# CONTROLSS_CMPSSA8_CONTROLSS_CMPSSA8 register map
Vendor: Texas Instruments
Peripheral module from a debugger description file (folder AM263).
Registers are 16-bit, read-write, reset 0x0 unless marked. A register's access mark holds for its fields unless they carry their own. Offsets are as the file gives them; lines under a group give offsets from that group; [hi:lo] are bit positions; {n}, {i} and the like mark numbered series; 'fields as' and 'values as' point back to an identical list; <NAME> marks a mode.

## CONTROLSS_CMPSSA8_CONTROLSS_CMPSSA8
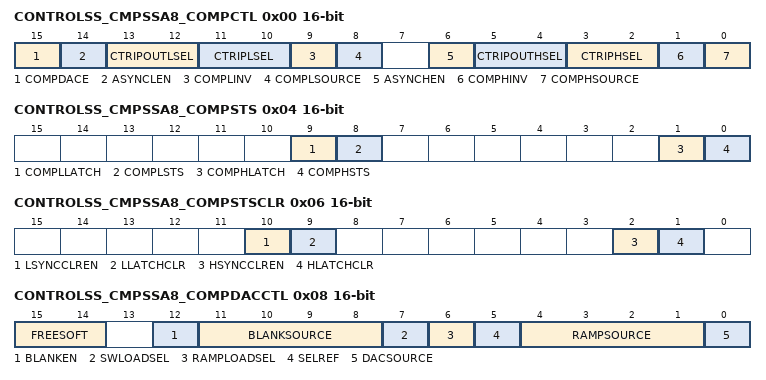
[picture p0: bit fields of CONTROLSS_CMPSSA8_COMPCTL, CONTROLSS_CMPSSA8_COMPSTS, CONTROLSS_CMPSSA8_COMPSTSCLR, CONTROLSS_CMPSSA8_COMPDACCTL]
0x00 CONTROLSS_CMPSSA8_COMPCTL
  [15] COMPDACE — Comparator/DAC enable. 0 Comparator/DAC disabled 1 Comparator/DAC enabled
  [14] ASYNCLEN — Low comparator asynchronous path enable. Allows asynchronous comparator output to feed into OR gate with latched digital filter signal when CTRIPLSEL=3 or CTRIPOUTLSEL=3. 0 Asynchronous comparator output does not feed into OR gate with latched digital filter output 1 Asynchronous comparator output feeds into OR gate with latched digital filter output
  [13:12] CTRIPOUTLSEL — Low comparator CTRIPOUTL source select. 0 Asynchronous comparator output drives CTRIPOUTL 1 Synchronous comparator output drives CTRIPOUTL 2 Output of digital filter drives CTRIPOUTL 3 Latched output of digital filter drives CTRIPOUTL
  [11:10] CTRIPLSEL — Low comparator CTRIPL source select. 0 Asynchronous comparator output drives CTRIPL 1 Synchronous comparator output drives CTRIPL 2 Output of digital filter drives CTRIPL 3 Latched output of digital filter drives CTRIPL
  [9] COMPLINV — Low comparator output invert. 0 Output of comparator is not inverted 1 Output of comparator is inverted
  [8] COMPLSOURCE — CompL Pos Mux Select0 positive mux selects INL_3p3v voltage (default)1 postive mux selects INH_3p3v
  [6] ASYNCHEN — High comparator asynchronous path enable. Allows asynchronous comparator output to feed into OR gate with latched digital filter signal when CTRIPHSEL=3 or CTRIPOUTHSEL=3. 0 Asynchronous comparator output does not feed into OR gate with latched digital filter output 1 Asynchronous comparator output feeds into OR gate with latched digital filter output
  [5:4] CTRIPOUTHSEL — High comparator CTRIPOUTH source select. 0 Asynchronous comparator output drives CTRIPOUTH 1 Synchronous comparator output drives CTRIPOUTH 2 Output of digital filter drives CTRIPOUTH 3 Latched output of digital filter drives CTRIPOUTH
  [3:2] CTRIPHSEL — High comparator CTRIPH source select. 0 Asynchronous comparator output drives CTRIPH 1 Synchronous comparator output drives CTRIPH 2 Output of digital filter drives CTRIPH 3 Latched output of digital filter drives CTRIPH
  [1] COMPHINV — High comparator output invert. 0 Output of comparator is not inverted 1 Output of comparator is inverted
  [0] COMPHSOURCE — CompH neg Mux slect0 negative mux selects DAC voltage (default)1 negative mux selects INL_3p3v
0x02 CONTROLSS_CMPSSA8_COMPHYSCTL
  [3:0] COMPHYS — Comparator hysteresis. Sets the amount of hysteresis on the comparator inputs. 0 None 1 Set to typical hysteresis 2 Set to 2x of typical hysteresis 3 Set to 3x of typical hysteresis 4 Set to 4x of typical hysteresis others : undefined
0x04 CONTROLSS_CMPSSA8_COMPSTS ro
  [9] COMPLLATCH — Latched value of low comparator digital filter output
  [8] COMPLSTS — Low comparator digital filter output
  [1] COMPHLATCH — Latched value of high comparator digital filter output
  [0] COMPHSTS — High comparator digital filter output
0x06 CONTROLSS_CMPSSA8_COMPSTSCLR access not given
  [10] LSYNCCLREN rw — Low comparator latch EPWMSYNCPER clear. Enable EPWMSYNCPER reset of low comparator digital filter output latch COMPSTS[COMPLLATCH]. 0 EPWMSYNCPER will not reset latch 1 EPWMSYNCPER will reset latch
  [9] LLATCHCLR — Low comparator latch software clear. Perform software reset of low comparator digital filter output latch COMPSTS[COMPLLATCH]. Reads always return 0. 0 No effect 1 Generate a single pulse of latch reset signal for COMPSTS[COMPLLATCH] (access RW RRETURNS0S)
  [2] HSYNCCLREN rw — High comparator latch EPWMSYNCPER clear. Enable EPWMSYNCPER reset of high comparator digital filter output latch COMPSTS[COMPHLATCH]. 0 EPWMSYNCPER will not reset latch 1 EPWMSYNCPER will reset latch
  [1] HLATCHCLR — High comparator latch software clear. Perform software reset of high comparator digital filter output latch COMPSTS[COMPHLATCH]. Reads always return 0. 0 No effect 1 Generate a single pulse of latch reset signal for COMPSTS[COMPHLATCH] (access RW RRETURNS0S)
0x08 CONTROLSS_CMPSSA8_COMPDACCTL
  [15:14] FREESOFT — Free-run or software-run emulation behavior. Behavior of the ramp generator during emulation suspend. 00b Ramp generator stops immediately during emulation suspend 01b Ramp generator completes current ramp and stops at next EPWMSYNCPER during emulation suspend 1Xb Ramp generator runs freely
  [12] BLANKEN — EPWMBLANK enable. This bit enables the EPWMBLANK signal. 0 EPWMBLANK signal is disabled. 1 EPWMBLANK signal is enabled.
  [11:8] BLANKSOURCE — EPWMBLANK source select. This bit field determines which EPWMnBLANK is passed on as the EPWMBLANK signal. Where n represents the maximum number of EPWMBLANK signals available on the device: 0 EPWM1BLANK 1 EPWM2BLANK 2 EPWM3BLANK ... n-1 EPWMnBLANK
  [7] SWLOADSEL — Software load select. Determines whether DACxVALA is updated from DACxVALS on SYSCLK or EPWMSYNCPER. 0 DACxVALA is updated from DACxVALS on SYSCLK 1 DACxVALA is updated from DACxVALS on EPWMSYNCPER
  [6] RAMPLOADSEL — Ramp load select. Determines whether RAMPSTS is updated from RAMPMAXREFA or RAMPMAXREFS when COMPSTS[COMPHSTS] is triggered. 0 RAMPSTS is loaded from RAMPMAXREFA 1 RAMPSTS is loaded from RAMPMAXREFS
  [5] SELREF — CMPSS reference select0 vref_1p8v as reference voltage (default)1 vdd_1p8v as reference voltage
  [4:1] RAMPSOURCE — EPWMSYNCPER source select. Determines which EPWMnSYNCPER signal is used within the CMPSS module. Where n represents the maximum number of EPWMSYNCPER signals available on the device: 0 EPWM1SYNCPER 1 EPWM2SYNCPER 2 EPWM3SYNCPER ... n-1 EPWMnSYNCPER
  [0] DACSOURCE — DAC source select. Determines whether DACHVALA is updated from DACHVALS or from the ramp generator. 0 DACHVALA is updated from DACHVALS 1 DACHVALA is updated from the ramp generator
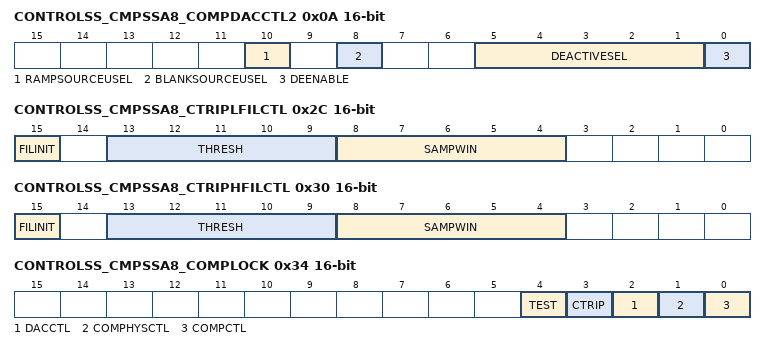
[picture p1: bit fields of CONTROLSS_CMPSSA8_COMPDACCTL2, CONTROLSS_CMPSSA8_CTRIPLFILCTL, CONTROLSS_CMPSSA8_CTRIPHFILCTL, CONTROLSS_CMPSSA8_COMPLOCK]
0x0A CONTROLSS_CMPSSA8_COMPDACCTL2
  [10] RAMPSOURCEUSEL — 0: Selects EPWM0 to 15 as RAMP source 1: Selects EPWM16 to 31 as RAMP source
  [8] BLANKSOURCEUSEL — 0: Selects EPWM0 to 15 as blank source 1: Selects EPWM16 to 31 as blank source
  [5:1] DEACTIVESEL — DEACTIVE source select: 0x0 : EPWM1.DEACTIVE 0x1 : EPWM2.DEACTIVE 0x2 : EPWM3.DEACTIVE 0x3 : EPWM4.DEACTIVE . . 0x31 : EPWM32.DEACTIVE
  [0] DEENABLE — DE mode enable. 0 DE mode features disabled. 1 DE mode features enabled.
0x0C CONTROLSS_CMPSSA8_DACHVALS
  [11:0] DACVAL — High DAC shadow value. When COMPDACCTL[DACSOURCE]=0, the value of DACHVALS is loaded into DACHVALA on the trigger signal selected by COMPDACCTL[SWLOADSEL].
0x0E CONTROLSS_CMPSSA8_DACHVALA ro
  [11:0] DACVAL — High DAC active value. Value that is actively driven by the high DAC.
0x10 CONTROLSS_CMPSSA8_RAMPMAXREFA ro
  [15:0] RAMPMAXREF — Ramp maximum reference active value. Latched value to be loaded into ramp generator RAMPSTS.
0x14 CONTROLSS_CMPSSA8_RAMPMAXREFS
  [15:0] RAMPMAXREF — Ramp maximum reference shadow. Unlatched value to be loaded into ramp generator RAMPSTS.
0x18 CONTROLSS_CMPSSA8_RAMPDECVALA ro
  [15:0] RAMPDECVAL — Ramp decrement value active. Latched value that will be subtracted from RAMPSTS.
0x1C CONTROLSS_CMPSSA8_RAMPDECVALS
  [15:0] RAMPDECVAL — Ramp decrement value shadow. Unlatched value to be loaded into RAMPDECVALA.
0x20 CONTROLSS_CMPSSA8_RAMPSTS ro
  [15:0] RAMPVALUE — Ramp value. Present value of ramp generator.
0x24 CONTROLSS_CMPSSA8_DACLVALS
  [11:0] DACVAL — Low DAC shadow value. value to be loaded into DACLVALA on the trigger signal selected by COMPDACCTL[SWLOADSEL].
0x26 CONTROLSS_CMPSSA8_DACLVALA ro
  [11:0] DACVAL — Low DAC active value. Value that is actively driven by the low DAC.
0x28 CONTROLSS_CMPSSA8_RAMPDLYA ro
  [12:0] DELAY — Ramp delay active value. Latched value of the number of cycles to delay the start of the ramp generator decrementer after a EPWMSYNCPER is received.
0x2A CONTROLSS_CMPSSA8_RAMPDLYS
  [12:0] DELAY — Ramp delay shadow value. Unlatched value to be loaded into RAMPDLYA.
0x2C CONTROLSS_CMPSSA8_CTRIPLFILCTL access not given
  [15] FILINIT — Low filter initialization. 0 No effect 1 Initialize all samples to the filter input value (access RW RRETURNS0S)
  [13:9] THRESH rw — Low filter majority voting threshold. At least THRESH samples of the opposite state must appear within the sample window in order for the output to change state. Threshold used is THRESH+1.
  [8:4] SAMPWIN rw — Low filter sample window size. Number of samples to monitor is SAMPWIN+1.
0x2E CONTROLSS_CMPSSA8_CTRIPLFILCLKCTL
  [15:0] CLKPRESCALE — Low filter sample clock prescale. Number of system clocks between samples is CLKPRESCALE+1.
0x30 CONTROLSS_CMPSSA8_CTRIPHFILCTL access not given
  [15] FILINIT — High filter initialization. 0 No effect 1 Initialize all samples to the filter input value (access RW RRETURNS0S)
  [13:9] THRESH rw — High filter majority voting threshold. At least THRESH samples of the opposite state must appear within the sample window in order for the output to change state. Threshold used is THRESH+1.
  [8:4] SAMPWIN rw — High filter sample window size. Number of samples to monitor is SAMPWIN+1.
0x32 CONTROLSS_CMPSSA8_CTRIPHFILCLKCTL
  [15:0] CLKPRESCALE — High filter sample clock prescale. Number of system clocks between samples is CLKPRESCALE+1.
0x34 CONTROLSS_CMPSSA8_COMPLOCK access not given
  [4] TEST — TEST Lock. This bit, when set, will prevent any further writes to the any undocumented registers that may affect the performance/behavior of this block. Once set this bit can only be cleared by a reset. (access RW SONCE)
  [3] CTRIP — Lock write-access to the CTRIPxFILTCTL and CTRIPxFILCLKCTL registers. 0 CTRIPxFILCTL and CTRIPxFILCLKCTL registers are not locked. Write 0 to this bit has no effect. 1 CTRIPxFILCTL and CTRIPxFILCLKCTL registers are locked. Only a system reset can clear this bit. (access RW SONCE)
  [2] DACCTL — Lock write-access to the DACCTL register. 0 DACCTL register is not locked. Write 0 to this bit has no effect. 1 DACCTL register is locked. Only a system reset can clear this bit. (access RW SONCE)
  [1] COMPHYSCTL — Lock write-access to the COMPHYSCTL register. 0 COMPHYSCTL register is not locked. Write 0 to this bit has no effect. 1 COMPHYSCTL register is locked. Only a system reset can clear this bit. (access RW SONCE)
  [0] COMPCTL — Lock write-access to the COMPCTL register. 0 COMPCTL register is not locked. Write 0 to this bit has no effect. 1 COMPCTL register is locked. Only a system reset can clear this bit. (access RW SONCE)
0x38 CONTROLSS_CMPSSA8_DACHVALS2
  [11:0] DACVAL — High DAC shadow register2 value. When COMPDACCTL[DACSOURCE]=0, the value of DACHVALS2 is loaded into DACHVALA when DE mode is enabled and selected DEACTIVE input is asserted.
0x3A CONTROLSS_CMPSSA8_DACLVALS2
  [11:0] DACVAL — Low DAC shadow register2 value. Value of DACHVALS2 is loaded into DACHVALA when DE mode is enabled and selected DEACTIVE input is asserted.
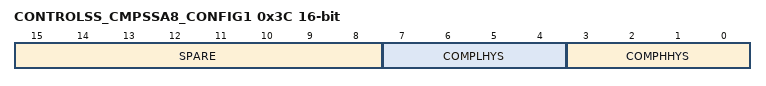
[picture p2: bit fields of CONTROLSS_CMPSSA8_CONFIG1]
0x3C CONTROLSS_CMPSSA8_CONFIG1
  [15:8] SPARE
  [7:4] COMPLHYS — compL Hysterisishystl_1p1v[3] = reservedhystl_1p1v[2] = control which comparator output value the hysteresis is applied tohystl_1p1v[1:0] = hysteresis value00 0 LSB01 17.5 LSB10 35 LSB11 52.5 LSB
  [3:0] COMPHHYS — CompH Hysteresishysth_1p1v[3] = reservedhysth_1p1v[2] 0 comparator hysteresis is applied when the comparator output is 1'b11 comparator hysteresis is applied when the comparator output is 1'b0hysth_1p1v[1:0] = hysteresis value00 0 LSB01 17.5 LSB10 35 LSB11 52.5 LSB
